# HDSC_HC32L073KATA register map
Vendor: HDSC Co.Ltd; Series: ARMCM0P; File version: 1.2
CPU: CM0 r0p0, little endian, no MPU, no FPU, 3 interrupt priority bits
Registers are 32-bit, read-write, reset 0x0 unless marked. A register's access mark holds for its fields unless they carry their own. Offsets are from the block's base; [hi:lo] are bit positions; {n}, {i} and the like mark numbered series; 'fields as' and 'values as' point back to an identical list.

## TIM0_MODE0
Base 0x40000C00
Same registers: TIM1_MODE0 0x40000D00, TIM2_MODE0 0x40000E00, TIM3_MODE0 0x40005800
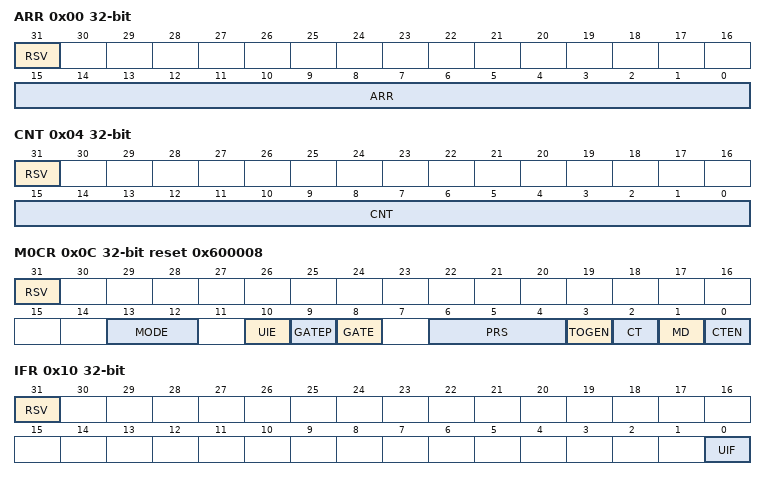
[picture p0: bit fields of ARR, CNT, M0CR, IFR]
0x00 ARR (reset mask 0xFFFF)
  [31] RSV, [15:0] ARR
0x04 CNT (reset mask 0xFFFF)
  [31] RSV, [15:0] CNT
0x08 CNT32
0x0C M0CR reset 0x600008 (reset mask 0x377F)
  [31] RSV, [13:12] MODE, [10] UIE, [9] GATEP, [8] GATE, [6:4] PRS, [3] TOGEN, [2] CT, [1] MD, [0] CTEN
0x10 IFR ro (reset mask 0x1)
  [31] RSV rw, [0] UIF
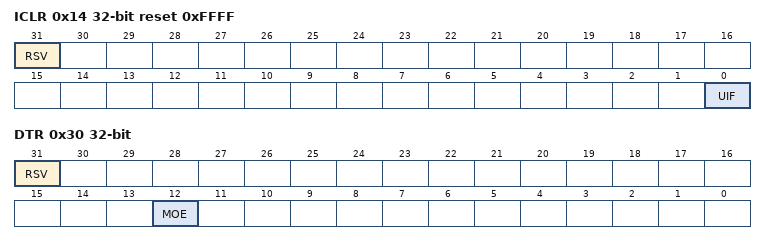
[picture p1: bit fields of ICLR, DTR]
0x14 ICLR wo reset 0xFFFF (reset mask 0x1)
  [31] RSV rw, [0] UIF
0x30 DTR (reset mask 0x1000)
  [31] RSV, [12] MOE

## TIM0_MODE1
Base 0x40000C00; alternate view of TIM0_MODE0
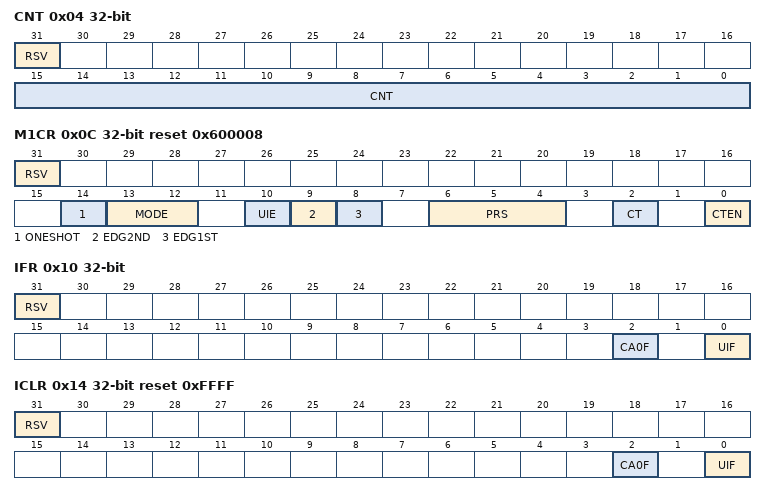
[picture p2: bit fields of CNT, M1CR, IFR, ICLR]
0x04 CNT (reset mask 0xFFFF)
  [31] RSV, [15:0] CNT
0x0C M1CR reset 0x600008 (reset mask 0x7775)
  [31] RSV, [14] ONESHOT, [13:12] MODE, [10] UIE, [9] EDG2ND, [8] EDG1ST, [6:4] PRS, [2] CT, [0] CTEN
0x10 IFR ro (reset mask 0x5)
  [31] RSV rw, [2] CA0F, [0] UIF
0x14 ICLR wo reset 0xFFFF (reset mask 0x5)
  [31] RSV rw, [2] CA0F, [0] UIF
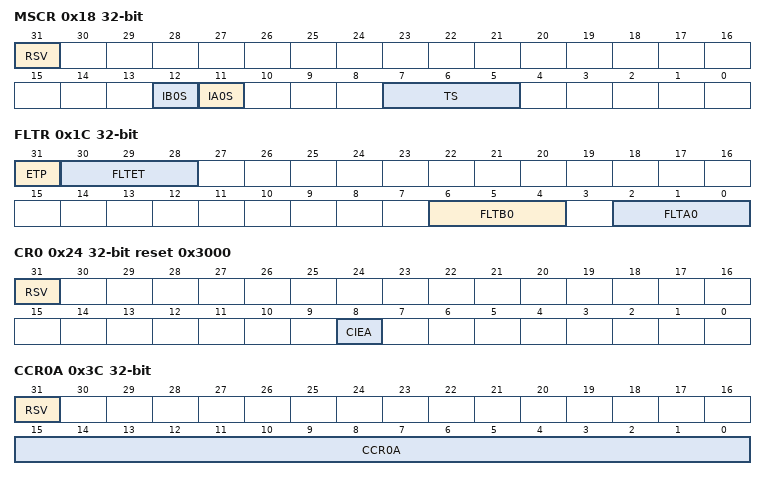
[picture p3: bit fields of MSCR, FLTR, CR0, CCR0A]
0x18 MSCR (reset mask 0x18E0)
  [31] RSV, [12] IB0S, [11] IA0S, [7:5] TS
0x1C FLTR
  [31] ETP, [30:28] FLTET, [6:4] FLTB0, [2:0] FLTA0
0x24 CR0 reset 0x3000 (reset mask 0x100)
  [31] RSV, [8] CIEA
0x3C CCR0A (reset mask 0xFFFF)
  [31] RSV, [15:0] CCR0A

## TIM1_MODE1
Base 0x40000D00; alternate view of TIM1_MODE0
Registers as TIM0_MODE1.

## TIM2_MODE1
Base 0x40000E00; alternate view of TIM2_MODE0
Registers as TIM0_MODE1.

## TIM3_MODE1
Base 0x40005800; alternate view of TIM3_MODE0
Registers as TIM0_MODE1.

## TIM0_MODE23
Base 0x40000C00; alternate view of TIM0_MODE0
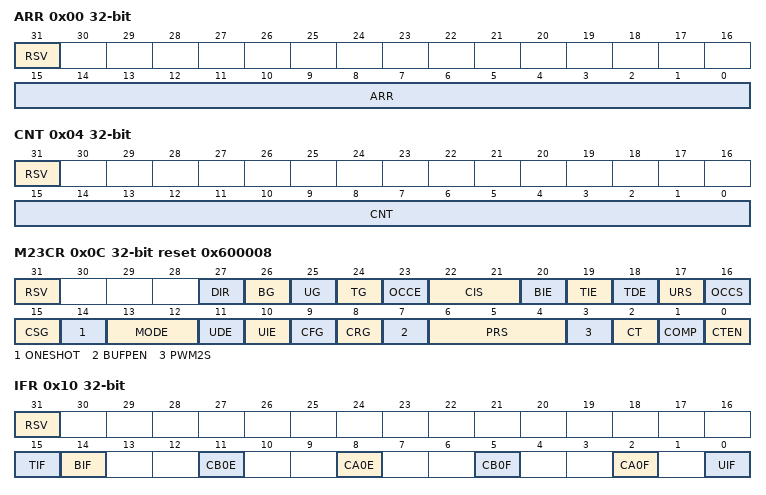
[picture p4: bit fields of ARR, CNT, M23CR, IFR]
0x00 ARR (reset mask 0xFFFF)
  [31] RSV, [15:0] ARR
0x04 CNT (reset mask 0xFFFF)
  [31] RSV, [15:0] CNT
0x0C M23CR reset 0x600008 (reset mask 0xFFFFFFF)
  [31] RSV, [27] DIR, [26] BG wo, [25] UG wo, [24] TG wo, [23] OCCE, [22:21] CIS, [20] BIE, [19] TIE, [18] TDE, [17] URS, [16] OCCS, [15] CSG, [14] ONESHOT, [13:12] MODE, [11] UDE, [10] UIE, [9] CFG, [8] CRG, [7] BUFPEN, [6:4] PRS, [3] PWM2S, [2] CT, [1] COMP, [0] CTEN
0x10 IFR ro (reset mask 0xC925)
  [31] RSV rw, [15] TIF, [14] BIF, [11] CB0E, [8] CA0E, [5] CB0F, [2] CA0F, [0] UIF
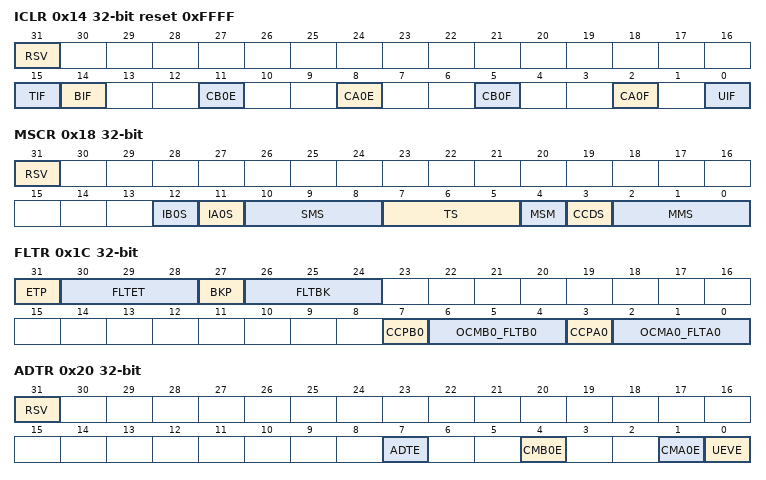
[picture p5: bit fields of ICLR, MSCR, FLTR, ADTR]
0x14 ICLR wo reset 0xFFFF (reset mask 0xC925)
  fields as IFR
0x18 MSCR (reset mask 0x1FFF)
  [31] RSV, [12] IB0S, [11] IA0S, [10:8] SMS, [7:5] TS, [4] MSM, [3] CCDS, [2:0] MMS
0x1C FLTR
  [31] ETP, [30:28] FLTET, [27] BKP, [26:24] FLTBK, [7] CCPB0, [6:4] OCMB0_FLTB0, [3] CCPA0, [2:0] OCMA0_FLTA0
0x20 ADTR (reset mask 0x93)
  [31] RSV, [7] ADTE, [4] CMB0E, [1] CMA0E, [0] UEVE
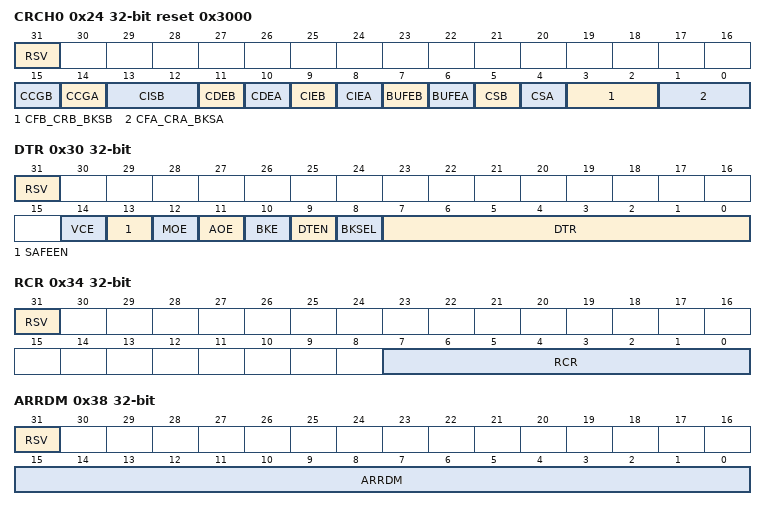
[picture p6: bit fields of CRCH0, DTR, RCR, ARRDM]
0x24 CRCH0 reset 0x3000 (reset mask 0xFFFF)
  [31] RSV, [15] CCGB, [14] CCGA, [13:12] CISB, [11] CDEB, [10] CDEA, [9] CIEB, [8] CIEA, [7] BUFEB, [6] BUFEA, [5] CSB, [4] CSA, [3:2] CFB_CRB_BKSB, [1:0] CFA_CRA_BKSA
0x30 DTR (reset mask 0xFFFF)
  [31] RSV, [14] VCE, [13] SAFEEN, [12] MOE, [11] AOE, [10] BKE, [9] DTEN, [8] BKSEL, [7:0] DTR
0x34 RCR (reset mask 0xFF)
  [31] RSV, [7:0] RCR
0x38 ARRDM (reset mask 0xFFFF)
  [31] RSV, [15:0] ARRDM
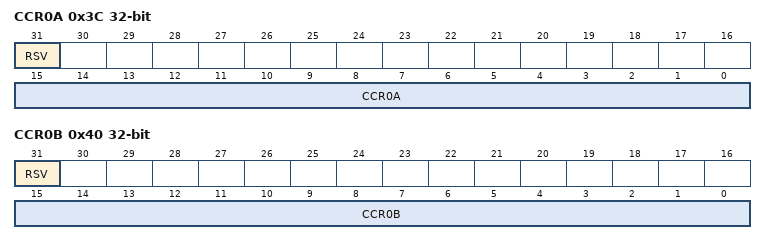
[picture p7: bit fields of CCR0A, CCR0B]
0x3C CCR0A (reset mask 0xFFFF)
  [31] RSV, [15:0] CCR0A
0x40 CCR0B (reset mask 0xFFFF)
  [31] RSV, [15:0] CCR0B

## TIM1_MODE23
Base 0x40000D00; alternate view of TIM1_MODE0
Registers as TIM0_MODE23.

## TIM2_MODE23
Base 0x40000E00; alternate view of TIM2_MODE0
Registers as TIM0_MODE23.

## TIM3_MODE23
Base 0x40005800; alternate view of TIM3_MODE0
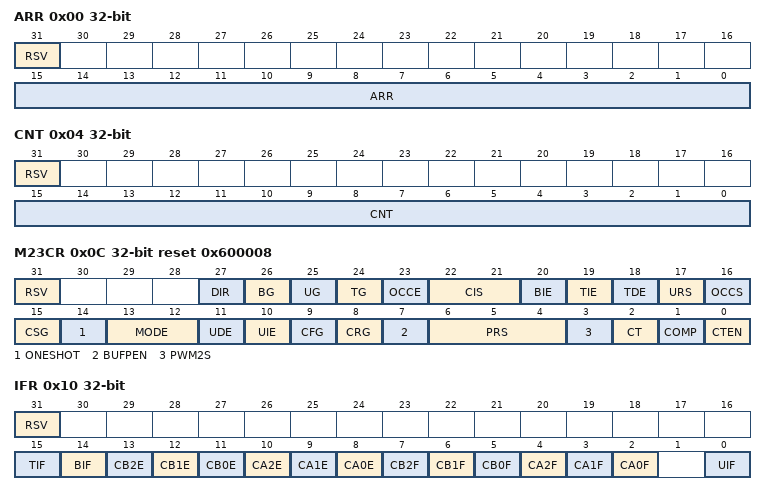
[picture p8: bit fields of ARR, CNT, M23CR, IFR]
0x00 ARR (reset mask 0xFFFF)
  [31] RSV, [15:0] ARR
0x04 CNT (reset mask 0xFFFF)
  [31] RSV, [15:0] CNT
0x0C M23CR reset 0x600008 (reset mask 0xFFFFFFF)
  [31] RSV, [27] DIR, [26] BG wo, [25] UG wo, [24] TG wo, [23] OCCE, [22:21] CIS, [20] BIE, [19] TIE, [18] TDE, [17] URS, [16] OCCS, [15] CSG, [14] ONESHOT, [13:12] MODE, [11] UDE, [10] UIE, [9] CFG, [8] CRG, [7] BUFPEN, [6:4] PRS, [3] PWM2S, [2] CT, [1] COMP, [0] CTEN
0x10 IFR ro (reset mask 0xFFFD)
  [31] RSV rw, [15] TIF, [14] BIF, [13] CB2E, [12] CB1E, [11] CB0E, [10] CA2E, [9] CA1E, [8] CA0E, [7] CB2F, [6] CB1F, [5] CB0F, [4] CA2F, [3] CA1F, [2] CA0F, [0] UIF
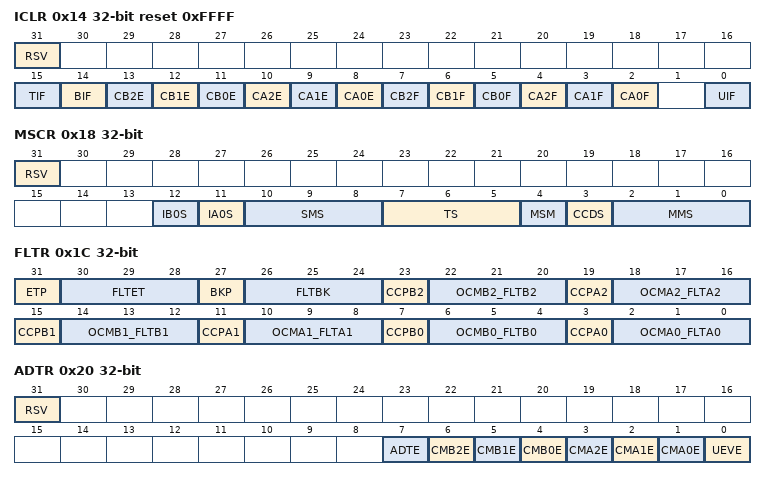
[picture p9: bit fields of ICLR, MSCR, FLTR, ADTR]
0x14 ICLR wo reset 0xFFFF (reset mask 0xFFFD)
  fields as IFR
0x18 MSCR (reset mask 0x1FFF)
  [31] RSV, [12] IB0S, [11] IA0S, [10:8] SMS, [7:5] TS, [4] MSM, [3] CCDS, [2:0] MMS
0x1C FLTR
  [31] ETP, [30:28] FLTET, [27] BKP, [26:24] FLTBK, [23] CCPB2, [22:20] OCMB2_FLTB2, [19] CCPA2, [18:16] OCMA2_FLTA2, [15] CCPB1, [14:12] OCMB1_FLTB1, [11] CCPA1, [10:8] OCMA1_FLTA1, [7] CCPB0, [6:4] OCMB0_FLTB0, [3] CCPA0, [2:0] OCMA0_FLTA0
0x20 ADTR (reset mask 0xFF)
  [31] RSV, [7] ADTE, [6] CMB2E, [5] CMB1E, [4] CMB0E, [3] CMA2E, [2] CMA1E, [1] CMA0E, [0] UEVE
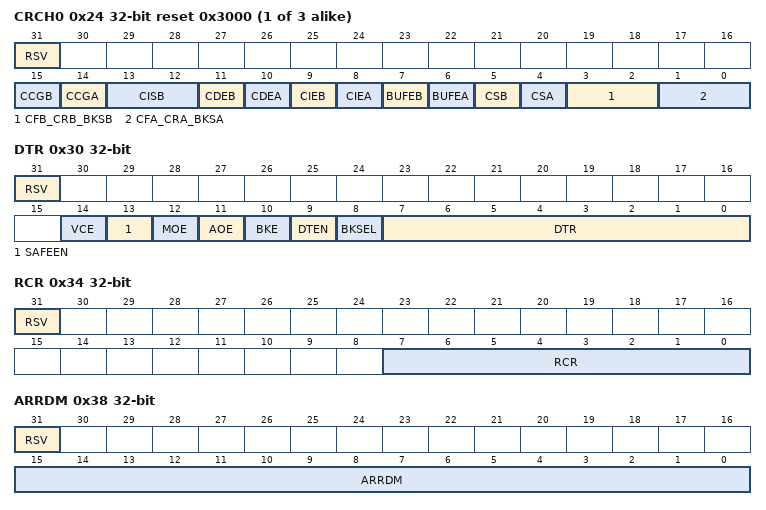
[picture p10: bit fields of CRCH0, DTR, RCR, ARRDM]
{0x24+4i} CRCH{i} reset 0x3000 (reset mask 0xFFFF) (i=0..2)
  [31] RSV, [15] CCGB, [14] CCGA, [13:12] CISB, [11] CDEB, [10] CDEA, [9] CIEB, [8] CIEA, [7] BUFEB, [6] BUFEA, [5] CSB, [4] CSA, [3:2] CFB_CRB_BKSB, [1:0] CFA_CRA_BKSA
0x30 DTR (reset mask 0xFFFF)
  [31] RSV, [14] VCE, [13] SAFEEN, [12] MOE, [11] AOE, [10] BKE, [9] DTEN, [8] BKSEL, [7:0] DTR
0x34 RCR (reset mask 0xFF)
  [31] RSV, [7:0] RCR
0x38 ARRDM (reset mask 0xFFFF)
  [31] RSV, [15:0] ARRDM
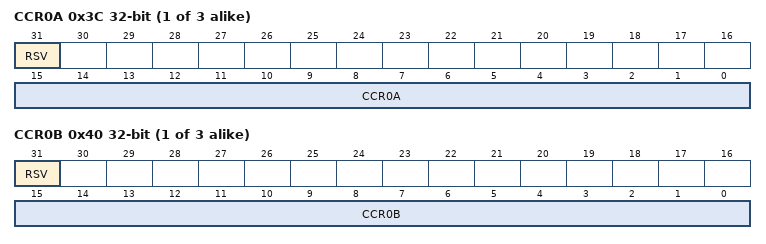
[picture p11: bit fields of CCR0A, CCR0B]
{0x3C+8i} CCR{i}A (reset mask 0xFFFF) (i=0..2)
  [31] RSV, [15:0] CCR{i}A
{0x40+8i} CCR{i}B (reset mask 0xFFFF) (i=0..2)
  [31] RSV, [15:0] CCR{i}B
